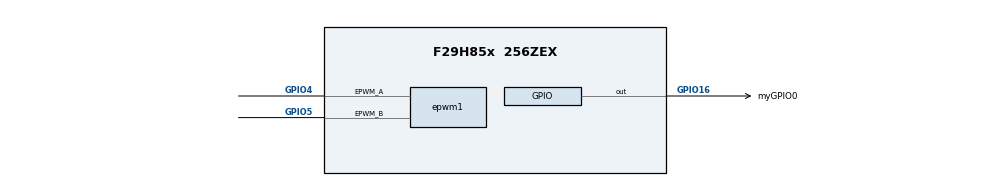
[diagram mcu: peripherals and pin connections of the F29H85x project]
/**
 * @cliArgs --device "F29H85x" --package "256ZEX" --part "F29H85x_256ZEX" --context "CPU1" --product "MCU_SDK_F29H85x@1.02.02.00"
 * @versions {"tool":"1.25.0+4237"}
 */

    
const divider15       = system.clockTree["PLL_REFDIV"];
divider15.divideValue = 1;

const multiplier1         = system.clockTree["PLL_IMULT"];
multiplier1.multiplyValue = 40;

const mux7       = system.clockTree["OSCCLKSRCSEL"];
mux7.inputSelect = "INTOSC2";

/**
 * Import the modules used in this configuration.
 */

const ecap             = scripting.addModule("/driverlib/ecap.js", {}, false);
const ecap1            = ecap.addInstance();
const epwm             = scripting.addModule("/driverlib/epwm.js", {}, false);
const epwm1            = epwm.addInstance();
const gpio             = scripting.addModule("/driverlib/gpio.js", {}, false);
const gpio1            = gpio.addInstance();
const inputxbar_input  = scripting.addModule("/driverlib/inputxbar_input.js", {}, false);
const inputxbar_input1 = inputxbar_input.addInstance();
const jtag             = scripting.addModule("/driverlib/jtag.js");

/**
 * Write custom configuration values to the imported modules.
 */
ecap1.$name                  = "myECAP0";
ecap1.captureMode            = "ECAP_ONE_SHOT_CAPTURE_MODE";
ecap1.eventStop              = "ECAP_EVENT_4";
ecap1.eventOnePolarity       = "ECAP_EVNT_FALLING_EDGE";
ecap1.eventThreePolarity     = "ECAP_EVNT_FALLING_EDGE";
ecap1.registerInterrupts     = true;
ecap1.enableInterrupt        = true;
ecap1.interruptSourceCapture = ["ECAP_ISR_SOURCE_CAPTURE_EVENT_4"];
ecap1.counterResetOnEvent    = ["ECAP_EVENT_1","ECAP_EVENT_2","ECAP_EVENT_3","ECAP_EVENT_4"];
ecap1.enableLoadCounter      = true;
ecap1.ecapInput              = "ECAP_INPUT_INPUTXBAR7";
ecap1.periphClock.$name      = "driverlib_perClock0";
ecap1.periphConfig.$name     = "driverlib_perConfig0";

epwm1.$name                                                 = "myEPWM0";
epwm1.epwm.$assign                                          = "EPWM1";
epwm1.epwmTimebase_period                                   = 500;
epwm1.epwmTimebase_phaseEnable                              = true;
epwm1.epwmActionQualifier_EPWM_AQ_OUTPUT_A_ON_TIMEBASE_ZERO = "EPWM_AQ_OUTPUT_TOGGLE";
epwm1.epwm.$assign                                          = "EPWM3";
epwm1.epwm.epwm_aPin.$assign                                = "GPIO4";
epwm1.epwm.epwm_bPin.$assign                                = "GPIO5";
epwm1.periphClock.$name                                     = "driverlib_perClock1";
epwm1.periphConfig.$name                                    = "driverlib_perConfig1";

gpio1.$name           = "myGPIO0";
gpio1.qualMode        = "GPIO_QUAL_ASYNC";
gpio1.gpioPin.$assign = "GPIO16";

inputxbar_input1.$name          = "myINPUTXBARINPUT0";
inputxbar_input1.inputxbarInput = "XBAR_INPUT7";
inputxbar_input1.inputxbarGpio  = "GPIO16";
